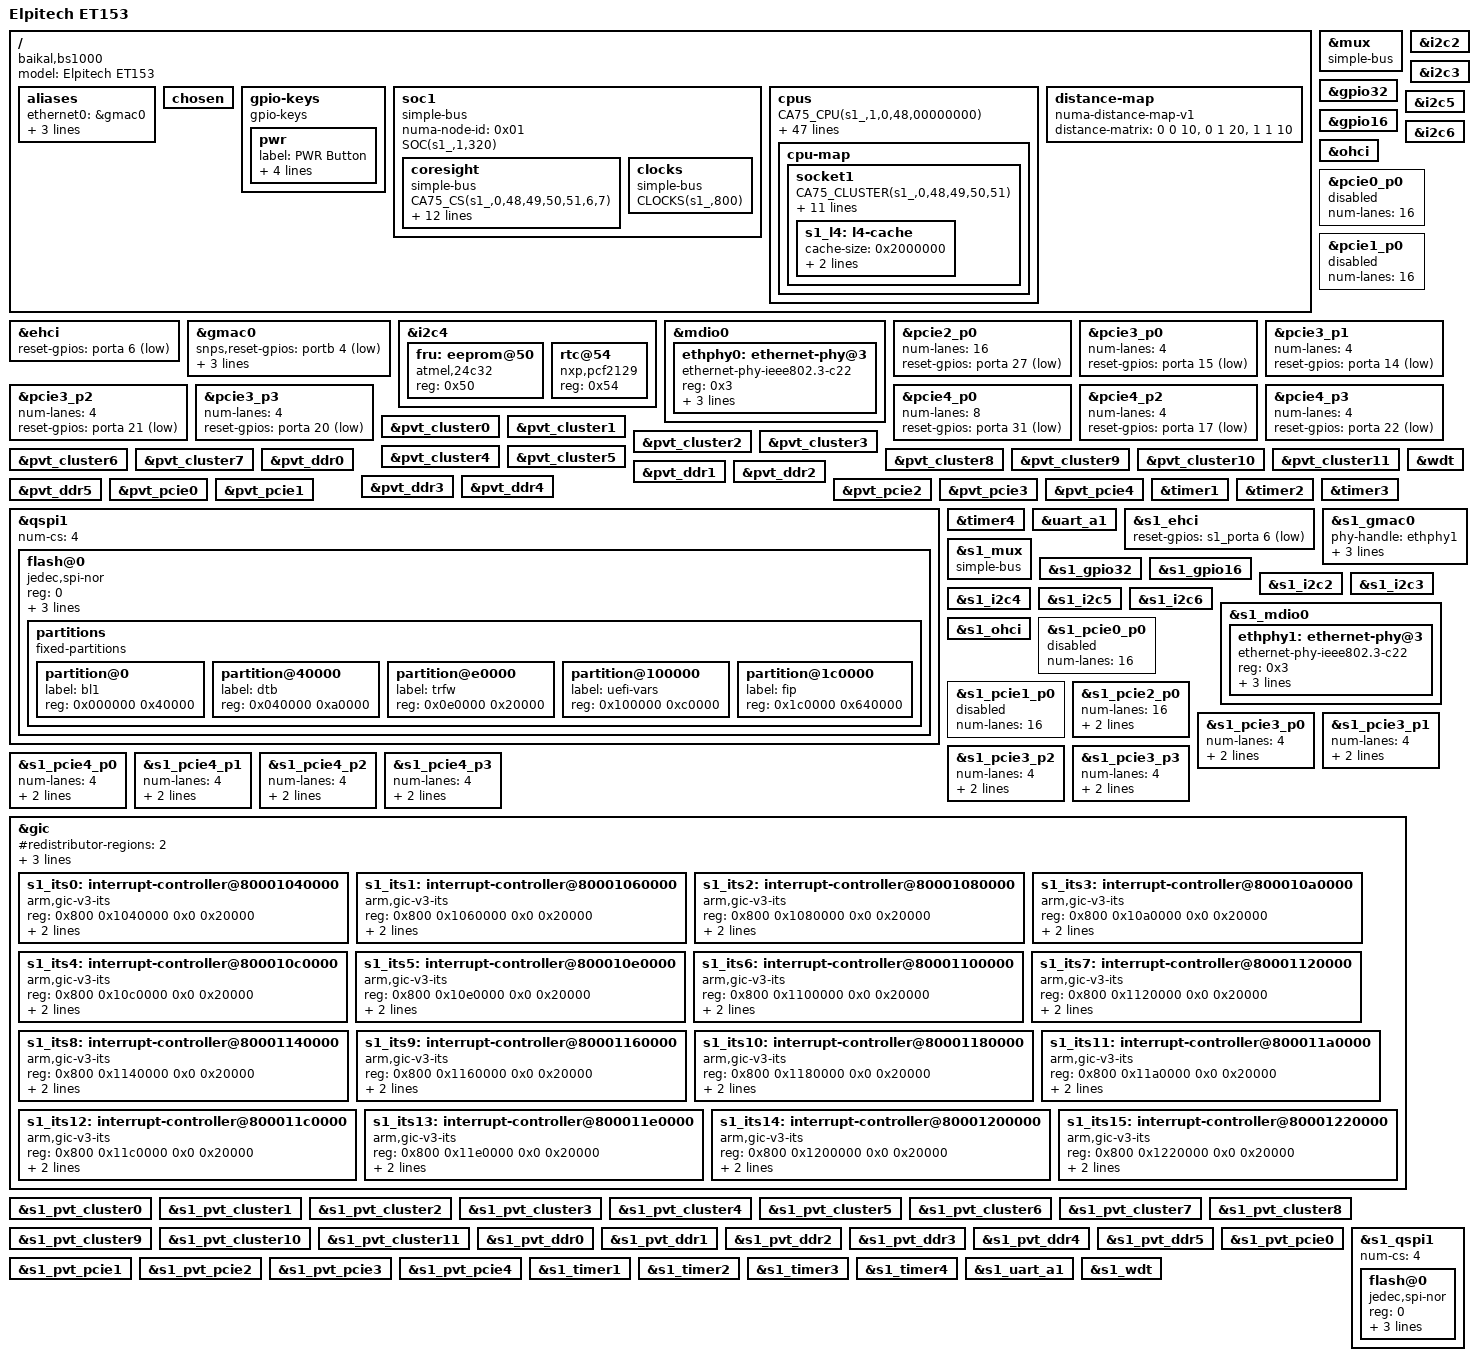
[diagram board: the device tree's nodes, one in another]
// SPDX-License-Identifier: GPL-2.0
/*
 * Device tree source for Baikal Electronics MBS-2S dual chip board
 * Copyright (C) 2023 Baikal Electronics, JSC
 */

/dts-v1/;

#include "bs1000.dtsi"
#include <dt-bindings/gpio/gpio.h>
#include <dt-bindings/input/gpio-keys.h>
#include <dt-bindings/net/realtek-phy-rtl8211f.h>

/ {
	model = "Elpitech ET153";
	compatible = "baikal,bs1000";

	aliases {
		ethernet0 = &gmac0;
		ethernet1 = &s1_gmac0;
		serial3	  = &s1_uart_a1;
		fru = &fru;
	};

	chosen { };

	gpio-keys {
		compatible = "gpio-keys";
		pwr {
			label = "PWR Button";
			linux,code = <116>;
			gpios = <&portb 11 GPIO_ACTIVE_LOW>;
			wakeup-source;
			wakeup-event-action = <EV_ACT_DEASSERTED>;
		};
	};

	/* Socket 1 */

	soc1 {
		compatible = "simple-bus";
		#address-cells = <2>;
		#size-cells = <2>;
		ranges = <0x0 0x0 0x800 0x0 0x800 0x0>;
		numa-node-id = <0x01>;

		SOC(s1_,1,320);

		/* CoreSight */
		coresight {
			compatible = "simple-bus";
			#address-cells = <2>;
			#size-cells = <2>;
			ranges;

			CA75_CS(s1_,0,48,49,50,51,6,7);
			CA75_CS(s1_,1,52,53,54,55,a,b);
			CA75_CS(s1_,2,56,57,58,59,e,f);
			CA75_CS(s1_,3,60,61,62,63,12,13);
			CA75_CS(s1_,4,64,65,66,67,16,17);
			CA75_CS(s1_,5,68,69,70,71,1a,1b);
			CA75_CS(s1_,6,72,73,74,75,1e,1f);
			CA75_CS(s1_,7,76,77,78,79,22,23);
			CA75_CS(s1_,8,80,81,82,83,26,27);
			CA75_CS(s1_,9,84,85,86,87,2a,2b);
			CA75_CS(s1_,a,88,89,90,91,2e,2f);
			CA75_CS(s1_,b,92,93,94,95,32,33);

			SOC_CS(s1_);
		};

		clocks {
			compatible = "simple-bus";
			#address-cells = <2>;
			#size-cells = <0>;

			CLOCKS(s1_,800);
		};

	};

	cpus {
		cpu-map {
			socket1 {
				CA75_CLUSTER(s1_,0,48,49,50,51);
				CA75_CLUSTER(s1_,1,52,53,54,55);
				CA75_CLUSTER(s1_,2,56,57,58,59);
				CA75_CLUSTER(s1_,3,60,61,62,63);
				CA75_CLUSTER(s1_,4,64,65,66,67);
				CA75_CLUSTER(s1_,5,68,69,70,71);
				CA75_CLUSTER(s1_,6,72,73,74,75);
				CA75_CLUSTER(s1_,7,76,77,78,79);
				CA75_CLUSTER(s1_,8,80,81,82,83);
				CA75_CLUSTER(s1_,9,84,85,86,87);
				CA75_CLUSTER(s1_,a,88,89,90,91);
				CA75_CLUSTER(s1_,b,92,93,94,95);

				s1_l4: l4-cache {
					cache-size = <0x2000000>;
					cache-unified;
					cache-level = <4>;
				};
			};
		};

		CA75_CPU(s1_,1,0,48,00000000);
		CA75_CPU(s1_,1,0,49,00000100);
		CA75_CPU(s1_,1,0,50,00000200);
		CA75_CPU(s1_,1,0,51,00000300);
		CA75_CPU(s1_,1,1,52,00010000);
		CA75_CPU(s1_,1,1,53,00010100);
		CA75_CPU(s1_,1,1,54,00010200);
		CA75_CPU(s1_,1,1,55,00010300);
		CA75_CPU(s1_,1,2,56,00020000);
		CA75_CPU(s1_,1,2,57,00020100);
		CA75_CPU(s1_,1,2,58,00020200);
		CA75_CPU(s1_,1,2,59,00020300);
		CA75_CPU(s1_,1,3,60,00030000);
		CA75_CPU(s1_,1,3,61,00030100);
		CA75_CPU(s1_,1,3,62,00030200);
		CA75_CPU(s1_,1,3,63,00030300);
		CA75_CPU(s1_,1,4,64,00040000);
		CA75_CPU(s1_,1,4,65,00040100);
		CA75_CPU(s1_,1,4,66,00040200);
		CA75_CPU(s1_,1,4,67,00040300);
		CA75_CPU(s1_,1,5,68,00050000);
		CA75_CPU(s1_,1,5,69,00050100);
		CA75_CPU(s1_,1,5,70,00050200);
		CA75_CPU(s1_,1,5,71,00050300);
		CA75_CPU(s1_,1,6,72,00060000);
		CA75_CPU(s1_,1,6,73,00060100);
		CA75_CPU(s1_,1,6,74,00060200);
		CA75_CPU(s1_,1,6,75,00060300);
		CA75_CPU(s1_,1,7,76,00070000);
		CA75_CPU(s1_,1,7,77,00070100);
		CA75_CPU(s1_,1,7,78,00070200);
		CA75_CPU(s1_,1,7,79,00070300);
		CA75_CPU(s1_,1,8,80,00080000);
		CA75_CPU(s1_,1,8,81,00080100);
		CA75_CPU(s1_,1,8,82,00080200);
		CA75_CPU(s1_,1,8,83,00080300);
		CA75_CPU(s1_,1,9,84,00090000);
		CA75_CPU(s1_,1,9,85,00090100);
		CA75_CPU(s1_,1,9,86,00090200);
		CA75_CPU(s1_,1,9,87,00090300);
		CA75_CPU(s1_,1,a,88,000a0000);
		CA75_CPU(s1_,1,a,89,000a0100);
		CA75_CPU(s1_,1,a,90,000a0200);
		CA75_CPU(s1_,1,a,91,000a0300);
		CA75_CPU(s1_,1,b,92,000b0000);
		CA75_CPU(s1_,1,b,93,000b0100);
		CA75_CPU(s1_,1,b,94,000b0200);
		CA75_CPU(s1_,1,b,95,000b0300);
	};

	distance-map {
		compatible = "numa-distance-map-v1";
		distance-matrix = <0 0 10>,
				  <0 1 20>,
				  <1 1 10>;
	};
};

/* Socket 0 */

&ehci {
	status = "okay";
	reset-gpios = <&porta 6 GPIO_ACTIVE_LOW>;
};

&gmac0 {
	status = "okay";
	snps,reset-gpios = <&portb 4 GPIO_ACTIVE_LOW>;
	snps,reset-delays-us = <10>, <10000>, <50000>;
	phy-handle = <&ethphy0>;
	phy-mode = "rgmii-rxid";
};

&mux {
	compatible = "simple-bus";
	status = "okay";
};

&gpio32 {
	status = "okay";
};

&gpio16 {
	status = "okay";
};

&i2c2 {
	status = "okay";
};

&i2c3 {
	status = "okay";
};

&i2c4 {
	status = "okay";

	fru: eeprom@50 {
		compatible = "atmel,24c32";
		reg = <0x50>;
	};

	rtc@54 {
		compatible = "nxp,pcf2129";
		reg = <0x54>;
	};
};

&i2c5 {
	status = "okay";
};

&i2c6 {
	status = "okay";
};

&mdio0 {
	ethphy0: ethernet-phy@3 {
		compatible = "ethernet-phy-ieee802.3-c22";
		reg = <0x3>;
		realtek,led-mode = <RTL8211F_LED_MODE_B>;
		realtek,led1-control = <RTL8211F_LINK10_100_1000>;
		realtek,led0-control = <RTL8211F_LINK10_ACT>;
	};
};

&ohci {
	status = "okay";
};

&pcie0_p0 {
	status = "disabled"; /* RC is engaged in interchip CCIX */
	num-lanes = <16>;
};

/delete-node/ &pcie0_p0_ep;

&pcie1_p0 {
	status = "disabled"; /* RC is engaged in interchip CCIX */
	num-lanes = <16>;
};

/delete-node/ &pcie1_p0_ep;

&pcie2_p0 {
	status = "okay";
	num-lanes = <16>;
	reset-gpios = <&porta 27 GPIO_ACTIVE_LOW>;
};

/delete-node/ &pcie2_p0_ep;

&pcie3_p0 {
	status = "okay";
	num-lanes = <4>;
	reset-gpios = <&porta 15 GPIO_ACTIVE_LOW>;
};

&pcie3_p1 {
	status = "okay";
	num-lanes = <4>;
	reset-gpios = <&porta 14 GPIO_ACTIVE_LOW>;
};

&pcie3_p2 {
	status = "okay";
	num-lanes = <4>;
	reset-gpios = <&porta 21 GPIO_ACTIVE_LOW>;
};

&pcie3_p3 {
	status = "okay";
	num-lanes = <4>;
	reset-gpios = <&porta 20 GPIO_ACTIVE_LOW>;
};

&pcie4_p0 {
	status = "okay";
	num-lanes = <8>;
	reset-gpios = <&porta 31 GPIO_ACTIVE_LOW>;
};

&pcie4_p2 {
	status = "okay";
	num-lanes = <4>;
	reset-gpios = <&porta 17 GPIO_ACTIVE_LOW>;
};

&pcie4_p3 {
	status = "okay";
	num-lanes = <4>;
	reset-gpios = <&porta 22 GPIO_ACTIVE_LOW>;
};

&pvt_cluster0 {
	status = "okay";
};

&pvt_cluster1 {
	status = "okay";
};

&pvt_cluster2 {
	status = "okay";
};

&pvt_cluster3 {
	status = "okay";
};

&pvt_cluster4 {
	status = "okay";
};

&pvt_cluster5 {
	status = "okay";
};

&pvt_cluster6 {
	status = "okay";
};

&pvt_cluster7 {
	status = "okay";
};

&pvt_cluster8 {
	status = "okay";
};

&pvt_cluster9 {
	status = "okay";
};

&pvt_cluster10 {
	status = "okay";
};

&pvt_cluster11 {
	status = "okay";
};

&pvt_ddr0 {
	status = "okay";
	/delete-property/ interrupts; /* DDR0 PVT interrupt is out of chip 0 range */
};

&pvt_ddr1 {
	status = "okay";
	/delete-property/ interrupts; /* DDR1 PVT interrupt is out of chip 0 range */
};

&pvt_ddr2 {
	status = "okay";
	/delete-property/ interrupts; /* DDR2 PVT interrupt is out of chip 0 range */
};

&pvt_ddr3 {
	status = "okay";
	/delete-property/ interrupts; /* DDR3 PVT interrupt is out of chip 0 range */
};

&pvt_ddr4 {
	status = "okay";
	/delete-property/ interrupts; /* DDR4 PVT interrupt is out of chip 0 range */
};

&pvt_ddr5 {
	status = "okay";
	/delete-property/ interrupts; /* DDR5 PVT interrupt is out of chip 0 range */
};

&pvt_pcie0 {
	status = "okay";
};

&pvt_pcie1 {
	status = "okay";
};

&pvt_pcie2 {
	status = "okay";
};

&pvt_pcie3 {
	status = "okay";
};

&pvt_pcie4 {
	status = "okay";
	/delete-property/ interrupts; /* PCIe4 PVT interrupt is out of chip 0 range */
};

&qspi1 {
	status = "okay";
	num-cs = <4>;

	flash@0 {
		compatible = "jedec,spi-nor";
		reg = <0>;
		spi-max-frequency = <10000000>;
		spi-tx-bus-width = <1>;
		spi-rx-bus-width = <1>;
		status = "okay";

		partitions {
			compatible = "fixed-partitions";
			#address-cells = <1>;
			#size-cells = <1>;

			partition@0 {
				label = "bl1";
				reg = <0x000000 0x40000>;
			};

			partition@40000 {
				label = "dtb";
				reg = <0x040000 0xa0000>;
			};

			partition@e0000 {
				label = "trfw";
				reg = <0x0e0000 0x20000>;
			};

			partition@100000 {
				label = "uefi-vars";
				reg = <0x100000 0xc0000>;
			};

			partition@1c0000 {
				label = "fip";
				reg = <0x1c0000 0x640000>;
			};
		};
	};
};

&timer1 {
	status = "okay";
};

&timer2 {
	status = "okay";
};

&timer3 {
	status = "okay";
};

&timer4 {
	status = "okay";
};

&uart_a1 {
	status = "okay";
};

&wdt {
	status = "okay";
};

/* Socket 1 */

&s1_ehci {
	status = "okay";
	reset-gpios = <&s1_porta 6 GPIO_ACTIVE_LOW>;
};

&s1_gmac0 {
	status = "okay";
	phy-handle = <&ethphy1>;
	snps,reset-gpios = <&s1_portb 4 GPIO_ACTIVE_LOW>;
	snps,reset-delays-us = <10>, <10000>, <50000>;
	phy-mode = "rgmii-rxid";
};

&s1_mux {
	compatible = "simple-bus";
	status = "okay";
};

&s1_gpio32 {
	status = "okay";
};

&s1_gpio16 {
	status = "okay";
};

&s1_i2c2 {
	status = "okay";
};

&s1_i2c3 {
	status = "okay";
};

&s1_i2c4 {
	status = "okay";
};

&s1_i2c5 {
	status = "okay";
};

&s1_i2c6 {
	status = "okay";
};

&s1_mdio0 {
	ethphy1: ethernet-phy@3 {
		compatible = "ethernet-phy-ieee802.3-c22";
		reg = <0x3>;
		realtek,led-mode = <RTL8211F_LED_MODE_B>;
		realtek,led1-control = <RTL8211F_LINK10_100_1000>;
		realtek,led0-control = <RTL8211F_LINK10_ACT>;
	};
};

&s1_ohci {
	status = "okay";
};

&s1_pcie0_p0 {
	status = "disabled"; /* RC is engaged in interchip CCIX */
	num-lanes = <16>;
};

/delete-node/ &s1_pcie0_p0_ep;

&s1_pcie1_p0 {
	status = "disabled"; /* RC is engaged in interchip CCIX */
	num-lanes = <16>;
};

/delete-node/ &s1_pcie1_p0_ep;

&s1_pcie2_p0 {
	status = "okay";
	num-lanes = <16>;
	reset-gpios = <&s1_porta 27 GPIO_ACTIVE_LOW>;
	cpu-addr-bits = <39>;
};

/delete-node/ &s1_pcie2_p0_ep;

&s1_pcie3_p0 {
	status = "okay";
	num-lanes = <4>;
	reset-gpios = <&s1_porta 15 GPIO_ACTIVE_LOW>;
	cpu-addr-bits = <40>;
};

&s1_pcie3_p1 {
	status = "okay";
	num-lanes = <4>;
	reset-gpios = <&s1_porta 14 GPIO_ACTIVE_LOW>;
	cpu-addr-bits = <40>;
};

&s1_pcie3_p2 {
	status = "okay";
	num-lanes = <4>;
	reset-gpios = <&s1_porta 21 GPIO_ACTIVE_LOW>;
	cpu-addr-bits = <40>;
};

&s1_pcie3_p3 {
	status = "okay";
	num-lanes = <4>;
	reset-gpios = <&s1_porta 20 GPIO_ACTIVE_LOW>;
	cpu-addr-bits = <40>;
};

&s1_pcie4_p0 {
	status = "okay";
	num-lanes = <4>;
	reset-gpios = <&s1_porta 31 GPIO_ACTIVE_LOW>;
	cpu-addr-bits = <40>;
	/delete-property/ interrupts; /* PCIe4 interrupts is out of chip 1 range */
	/delete-property/ interrupt-names;
};

&s1_pcie4_p1 {
	status = "okay";
	num-lanes = <4>;
	reset-gpios = <&s1_porta 29 GPIO_ACTIVE_LOW>;
	cpu-addr-bits = <40>;
	/delete-property/ interrupts; /* PCIe4 interrupts is out of chip 1 range */
	/delete-property/ interrupt-names;
};

&s1_pcie4_p2 {
	status = "okay";
	num-lanes = <4>;
	reset-gpios = <&s1_porta 25 GPIO_ACTIVE_LOW>;
	cpu-addr-bits = <40>;
	/delete-property/ interrupts; /* PCIe4 interrupts is out of chip 1 range */
	/delete-property/ interrupt-names;
};

&s1_pcie4_p3 {
	status = "okay";
	num-lanes = <4>;
	reset-gpios = <&s1_porta 23 GPIO_ACTIVE_LOW>;
	cpu-addr-bits = <40>;
	/delete-property/ interrupts; /* PCIe4 interrupts is out of chip 1 range */
	/delete-property/ interrupt-names;
};

/* Add GICR and ITS */
&gic {
	#redistributor-regions = <2>;
	reg = <0x0 0x1000000 0x0 0x10000>,	/* GICD */
	      <0x0 0x1240000 0x0 0x600000>,	/* GICR */
	      <0x800 0x1240000 0x0 0x600000>;	/* GICR */

	s1_its0: interrupt-controller@80001040000 {
		compatible = "arm,gic-v3-its";
		reg = <0x800 0x1040000 0x0 0x20000>;
		msi-controller;
		#msi-cells = <1>;
		numa-node-id = <1>;
	};
	s1_its1: interrupt-controller@80001060000 {
		compatible = "arm,gic-v3-its";
		reg = <0x800 0x1060000 0x0 0x20000>;
		msi-controller;
		#msi-cells = <1>;
		numa-node-id = <1>;
	};
	s1_its2: interrupt-controller@80001080000 {
		compatible = "arm,gic-v3-its";
		reg = <0x800 0x1080000 0x0 0x20000>;
		msi-controller;
		#msi-cells = <1>;
		numa-node-id = <1>;
	};
	s1_its3: interrupt-controller@800010a0000 {
		compatible = "arm,gic-v3-its";
		reg = <0x800 0x10a0000 0x0 0x20000>;
		msi-controller;
		#msi-cells = <1>;
		numa-node-id = <1>;
	};
	s1_its4: interrupt-controller@800010c0000 {
		compatible = "arm,gic-v3-its";
		reg = <0x800 0x10c0000 0x0 0x20000>;
		msi-controller;
		#msi-cells = <1>;
		numa-node-id = <1>;
	};
	s1_its5: interrupt-controller@800010e0000 {
		compatible = "arm,gic-v3-its";
		reg = <0x800 0x10e0000 0x0 0x20000>;
		msi-controller;
		#msi-cells = <1>;
		numa-node-id = <1>;
	};
	s1_its6: interrupt-controller@80001100000 {
		compatible = "arm,gic-v3-its";
		reg = <0x800 0x1100000 0x0 0x20000>;
		msi-controller;
		#msi-cells = <1>;
		numa-node-id = <1>;
	};
	s1_its7: interrupt-controller@80001120000 {
		compatible = "arm,gic-v3-its";
		reg = <0x800 0x1120000 0x0 0x20000>;
		msi-controller;
		#msi-cells = <1>;
		numa-node-id = <1>;
	};
	s1_its8: interrupt-controller@80001140000 {
		compatible = "arm,gic-v3-its";
		reg = <0x800 0x1140000 0x0 0x20000>;
		msi-controller;
		#msi-cells = <1>;
		numa-node-id = <1>;
	};
	s1_its9: interrupt-controller@80001160000 {
		compatible = "arm,gic-v3-its";
		reg = <0x800 0x1160000 0x0 0x20000>;
		msi-controller;
		#msi-cells = <1>;
		numa-node-id = <1>;
	};
	s1_its10: interrupt-controller@80001180000 {
		compatible = "arm,gic-v3-its";
		reg = <0x800 0x1180000 0x0 0x20000>;
		msi-controller;
		#msi-cells = <1>;
		numa-node-id = <1>;
	};
	s1_its11: interrupt-controller@800011a0000 {
		compatible = "arm,gic-v3-its";
		reg = <0x800 0x11a0000 0x0 0x20000>;
		msi-controller;
		#msi-cells = <1>;
		numa-node-id = <1>;
	};
	s1_its12: interrupt-controller@800011c0000 {
		compatible = "arm,gic-v3-its";
		reg = <0x800 0x11c0000 0x0 0x20000>;
		msi-controller;
		#msi-cells = <1>;
		numa-node-id = <1>;
	};
	s1_its13: interrupt-controller@800011e0000 {
		compatible = "arm,gic-v3-its";
		reg = <0x800 0x11e0000 0x0 0x20000>;
		msi-controller;
		#msi-cells = <1>;
		numa-node-id = <1>;
	};
	s1_its14: interrupt-controller@80001200000 {
		compatible = "arm,gic-v3-its";
		reg = <0x800 0x1200000 0x0 0x20000>;
		msi-controller;
		#msi-cells = <1>;
		numa-node-id = <1>;
	};
	s1_its15: interrupt-controller@80001220000 {
		compatible = "arm,gic-v3-its";
		reg = <0x800 0x1220000 0x0 0x20000>;
		msi-controller;
		#msi-cells = <1>;
		numa-node-id = <1>;
	};
};

&s1_pvt_cluster0 {
	status = "okay";
};

&s1_pvt_cluster1 {
	status = "okay";
};

&s1_pvt_cluster2 {
	status = "okay";
};

&s1_pvt_cluster3 {
	status = "okay";
};

&s1_pvt_cluster4 {
	status = "okay";
};

&s1_pvt_cluster5 {
	status = "okay";
};

&s1_pvt_cluster6 {
	status = "okay";
};

&s1_pvt_cluster7 {
	status = "okay";
};

&s1_pvt_cluster8 {
	status = "okay";
};

&s1_pvt_cluster9 {
	status = "okay";
};

&s1_pvt_cluster10 {
	status = "okay";
};

&s1_pvt_cluster11 {
	status = "okay";
};

&s1_pvt_ddr0 {
	status = "okay";
	/delete-property/ interrupts; /* DDR0 PVT interrupt is out of chip 1 range */
};

&s1_pvt_ddr1 {
	status = "okay";
	/delete-property/ interrupts; /* DDR1 PVT interrupt is out of chip 1 range */
};

&s1_pvt_ddr2 {
	status = "okay";
	/delete-property/ interrupts; /* DDR2 PVT interrupt is out of chip 1 range */
};

&s1_pvt_ddr3 {
	status = "okay";
	/delete-property/ interrupts; /* DDR3 PVT interrupt is out of chip 1 range */
};

&s1_pvt_ddr4 {
	status = "okay";
	/delete-property/ interrupts; /* DDR4 PVT interrupt is out of chip 1 range */
};

&s1_pvt_ddr5 {
	status = "okay";
	/delete-property/ interrupts; /* DDR5 PVT interrupt is out of chip 1 range */
};

&s1_pvt_pcie0 {
	status = "okay";
};

&s1_pvt_pcie1 {
	status = "okay";
};

&s1_pvt_pcie2 {
	status = "okay";
};

&s1_pvt_pcie3 {
	status = "okay";
	/delete-property/ interrupts; /* PCIe3 PVT interrupt is out of chip 1 range */
};

&s1_pvt_pcie4 {
	status = "okay";
	/delete-property/ interrupts; /* PCIe4 PVT interrupt is out of chip 1 range */
};

&s1_qspi1 {
	status = "okay";
	num-cs = <4>;

	flash@0 {
		compatible = "jedec,spi-nor";
		reg = <0>;
		#address-cells = <1>;
		#size-cells = <1>;
		spi-max-frequency = <10000000>;
		spi-tx-bus-width = <1>;
		spi-rx-bus-width = <1>;
		status = "okay";
	};
};

&s1_timer1 {
	status = "okay";
};

&s1_timer2 {
	status = "okay";
};

&s1_timer3 {
	status = "okay";
};

&s1_timer4 {
	status = "okay";
};

&s1_uart_a1 {
	status = "okay";
};

&s1_wdt {
	status = "okay";
};
